# pse84 register map
Vendor: Cypress Semiconductor; Series: PSE84; File version: 1.0
CPU: CM33 r0p1, little endian, MPU, FPU, VTOR, 3 interrupt priority bits
Registers are 32-bit, read-write, reset 0x0 unless marked. A register's access mark holds for its fields unless they carry their own. Offsets are from the block's base; [hi:lo] are bit positions; lines under a group give offsets from that group; {n}, {i} and the like mark numbered series; 'fields as' and 'values as' point back to an identical list; <NAME> marks a mode.

## SAR
Base 0x42E80000
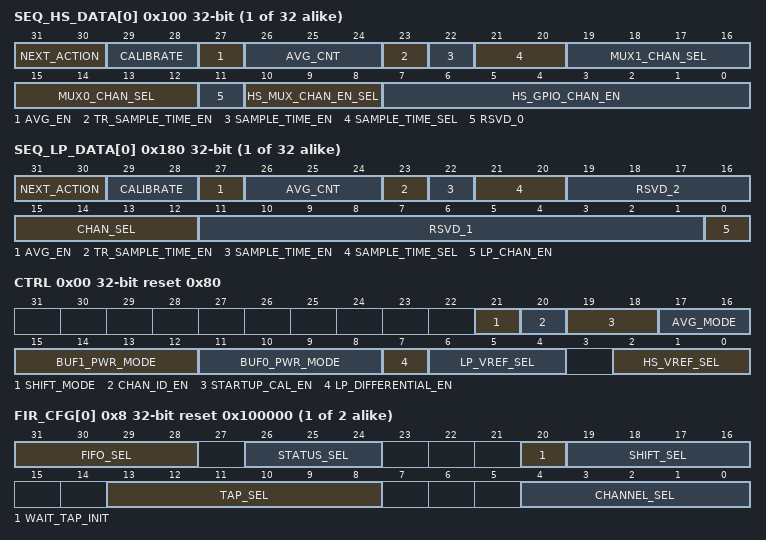
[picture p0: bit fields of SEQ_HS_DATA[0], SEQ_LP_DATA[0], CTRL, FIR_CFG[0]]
{0x100+4i} SEQ_HS_DATA[{i}] (i=0..31) — SAR Sequencer High Speed Data (only accessible if ACTRLR.STATUS.MODE=0)
  [31:30] NEXT_ACTION — Next Addr Field
    0=STOP (assert SAR_DONE and SAR_EOS condition and go to idle. This action is used to indicate the end of a scan.); 1=GO_TO_ENTRY_ADDR (assert SAR_EOS condition and jump to Entry Addr. This action is used for continuous operation. In continuous operation, disabling the SAR (AC.SAR_EN=0) is the only mechanism available to cease SAR operation (without disabling the entire AC).); 2=GO_TO_NEXT (Go to next addr. This action is used to continue to a next state in a given scan.); 3=RSVD (N/A)
  [29:28] CALIBRATE — Real Time Calibration Request. This signals the ADC to initiate a real-time calibration process during an ADC scan.
    0=DISABLED (Calibration Disabled); 1=OFFSET_AND_LINEARITY (Calibrate both Offset and Linearity); 2=OFFSET (Callibrate Offset only); 3=LINEARITY (Callibrate Linearity only)
  [27] AVG_EN — Average Enable This field is ignored if SAR_STA_CFG.CTRL.AVG_MODE=DISABLED. This field applies to all enabled channels (HS_GPIO_CHAN_EN and HS_MUX_CHAN_EN_SEL). 0 = averaging disabled 1 = averaging enabled If SAR_STA_CFG.CTRL.AVG_MODE=ACCUNDUMP, the enabled channels will be sampled, converted, and accumulated back to back (amount set by AVG_CNT). After AVG_CNT times, the accumulated results for each enabled channels are optionally shifted (set by SAR_STA_CFG.GPIO(MUX)_CHAN_CFG.AVG_SHIFT and SAR_STA_CFG.CTRL.SHIFT_MODE). If SAR_STA_CFG.CTRL.AVG_MODE=INTERLEAVED, the enabled channels will be sampled, converted, and accumulated once per scan (amount set by AVG_CNT). After AVG_CNT scans, the accumulated results for each enabled channels are optionally shifted (set by SAR_STA_CFG.GPIO(MUX)_CHAN_CFG.AVG_SHIFT and SAR_STA_CFG.CTRL.SHIFT_MODE). Requirements for using interleaved averaging: 1. The Entry Address state must have AVG_EN set. 2. The same value for AVG_CNT must be used across all states with AVG_EN set. 3. The AC cannot trigger the ADC with different multiple Entry Addresses (scans). 4. The SAR generates a SAR_DONE status at the end of every scan (unless confgured for continuous operation at which point only a SAR_EOS is generated), regardless of the value of AVG_CNT. If all channels in the scan are averaged, the AC can poll the SAR_RESULT or any of the SAR_(FIR)_FIFO_DONE triggers to determine when the averaged results are available. If only a subset of channels are averaged in a scan, it is up to the AC to count the number of scans to determine when the averaged results are available.
  [26:24] AVG_CNT — Averaging Count for channels that have averaging enabled (AVG_EN). A channel will be sampled and accumulated (1<<(AVG_CNT+1)) = [2..256] times. If SAR_STA_CFG.GPIO(MUX)_CHAN_CFG.AVG_SHIFT for an enabled channel is set, the accumulated samples are right shifted based on the value of SAR_STA_CFG.CTRL.SHIFT_MODE: SAR_STA_CFG.CTRL.SHIFT_MODE=TWELVE: After the last accumulation, the result is shifted back to 12 bits SAR_STA_CFG.CTRL.SHIFT_MODE=SIXTEEN: After the last accumulation, if avg_cnt >=32 the result will be shifted back to 16-bits, if avg_cnt < 32, no shift will be done as the result already is guaranteed to fit in 16 bits.
  [23] TR_SAMPLE_TIME_EN — Trigger Sample Time Enable. This field must always remain 0. For risk mitigation purposes only: this bit only applies to the first SAR table entry pointed to by the Autonomous Controller on a trigger if additional sample time is required. When this bit is set, the sample time on this first triggered table entry is SAR_STA_CFG.TR_SAMPLE_TIME.HS_SAMPLE_TIME. This only applies to when the table entry is first triggered. In continuous mode, when this table entry is executed again, the SAMPLE_TIME_EN/SAMPLE_TIME_SEL will be used.
  [22] SAMPLE_TIME_EN — Sample Time Enable. If this bit is set, then the start of conversion for this SAR table entry will be delayed by the sample time pointed to in SAMPLE_TIME_SEL
  [21:20] SAMPLE_TIME_SEL — Sample Time Select. Choose from 1 of 4 available Sample Times in SAR_STA_CFG.SAMPLE_TIME registers
  [19:16] MUX1_CHAN_SEL — MUX1 Channel Sel (See MUX0_CHAN_SEL) (This field is not used if HS_MUX_CHAN_EN_SEL = DISABLED or MUX0_SINGLE_ENDED or MUX0_PSEUDO_DIFF)
  [15:12] MUX0_CHAN_SEL — MUX0 Channel Sel (This field is not used if HS_MUX_CHAN_EN_SEL = DISABLED or MUX1_SINGLE_ENDED)
    {v}=MUX_CHANNEL_{v} (mux configured by settings in SAR_STA_CFG.MUX_CHAN_CFG{v}) (v=0..15)
  [11] RSVD_0
  [10:8] HS_MUX_CHAN_EN_SEL — Enable and Selection for HS Muxed SAR Channels
    0=DISABLED; 1=MUX0_SINGLE_ENDED (One Single Ended Conversion (configured by MUX0_CHAN_SEL)); 2=MUX1_SINGLE_ENDED (One Single Ended Conversion (configured by MUX1_CHAN_SEL)); 3=MUX0_AND_MUX1_SINGLE_ENDED (Two Simultaneously Sampled Single Ended Conversions (configured by MUX0_CHAN_SEL and MUX1_CHAN_SEL)); 4=MUX0_PSEUDO_DIFF (One Pseudo differential conversion (configured by MUX0_CHAN_SEL)); 5=RSVD_0 (N/A); 6=RSVD_1 (N/A); 7=RSVD_2 (N/A)
  [7:0] HS_GPIO_CHAN_EN — Enables for HS GPIO SAR Channels For each bit in this field: 0- HS GPIO SAR Channel is disabled 1- HS GPIO SAR Channel is enabled [0]: Channel 0, configured by SAR_STA_CFG.GPIO_CHAN_CFG0 [1]: Channel 1, configured by SAR_STA_CFG.GPIO_CHAN_CFG1 [2]: Channel 2, configured by SAR_STA_CFG.GPIO_CHAN_CFG2 [3]: Channel 3, configured by SAR_STA_CFG.GPIO_CHAN_CFG3 [4]: Channel 4, configured by SAR_STA_CFG.GPIO_CHAN_CFG4 [5]: Channel 5, configured by SAR_STA_CFG.GPIO_CHAN_CFG5 [6]: Channel 6, configured by SAR_STA_CFG.GPIO_CHAN_CFG6 [7]: Channel 7, configured by SAR_STA_CFG.GPIO_CHAN_CFG7
{0x180+4i} SEQ_LP_DATA[{i}] (i=0..31) — SAR Sequencer Low Power Data (only accessible if ACTRLR.STATUS.MODE=0)
  [31:30] NEXT_ACTION — Next Addr Field
    values as SEQ_HS_DATA[0].NEXT_ACTION
  [29:28] CALIBRATE — Real Time Calibration Request. This signals the ADC to initiate a real-time calibration process during an ADC scan.
    values as SEQ_HS_DATA[0].CALIBRATE
  [27] AVG_EN — Average Enable This field is ignored if SAR_STA_CFG.CTRL.AVG_MODE=DISABLED. This field applies to all enabled channels (HS_GPIO_CHAN_EN and HS_MUX_CHAN_EN_SEL). 0 = averaging disabled 1 = averaging enabled If SAR_STA_CFG.CTRL.AVG_MODE=ACCUNDUMP, the enabled channels will be sampled, converted, and accumulated back to back (amount set by AVG_CNT). After AVG_CNT times, the accumulated results for each enabled channels are optionally shifted (set by SAR_STA_CFG.GPIO(MUX)_CHAN_CFG.AVG_SHIFT and SAR_STA_CFG.CTRL.SHIFT_MODE). If SAR_STA_CFG.CTRL.AVG_MODE=INTERLEAVED, the enabled channels will be sampled, converted, and accumulated once per scan (amount set by AVG_CNT). After AVG_CNT scans, the accumulated results for each enabled channels are optionally shifted (set by SAR_STA_CFG.GPIO(MUX)_CHAN_CFG.AVG_SHIFT and SAR_STA_CFG.CTRL.SHIFT_MODE). Requirements for using interleaved averaging: 1. The Entry Address state must have AVG_EN set. 2. The same value for AVG_CNT must be used across all states with AVG_EN set. 3. The AC cannot trigger the ADC with different multiple Entry Addresses (scans). 4. The SAR generates a SAR_DONE status at the end of every scan (unless confgured for continuous operation at which point only a SAR_EOS is generated), regardless of the value of AVG_CNT. If all channels in the scan are averaged, the AC can poll the SAR_RESULT or any of the SAR_(FIR)_FIFO_DONE triggers to determine when the averaged results are available. If only a subset of channels are averaged in a scan, it is up to the AC to count the number of scans to determine when the averaged results are available.
  [26:24] AVG_CNT — Averaging Count for channels that have averaging enabled (AVG_EN). A channel will be sampled and accumulated (1<<(AVG_CNT+1)) = [2..256] times. If SAR_STA_CFG.GPIO(MUX)_CHAN_CFG.AVG_SHIFT for an enabled channel is set, the accumulated samples are right shifted based on the value of SAR_STA_CFG.CTRL.SHIFT_MODE: SAR_STA_CFG.CTRL.SHIFT_MODE=TWELVE: After the last accumulation, the result is shifted back to 12 bits SAR_STA_CFG.CTRL.SHIFT_MODE=SIXTEEN: After the last accumulation, if avg_cnt >=32 the result will be shifted back to 16-bits, if avg_cnt < 32, no shift will be done as the result already is guaranteed to fit in 16 bits.
  [23] TR_SAMPLE_TIME_EN — Trigger Sample Time Enable. This field must always remain 0. For risk mitigation purposes only: this bit only applies to the first SAR table entry pointed to by the Autonomous Controller on a trigger if additional sample time is required. When this bit is set, the sample time on this first triggered table entry is SAR_STA_CFG.TR_SAMPLE_TIME.LP_SAMPLE_TIME. This only applies to when the table entry is first triggered. In continuous mode, when this table entry is executed again, the SAMPLE_TIME_EN/SAMPLE_TIME_SEL will be used.
  [22] SAMPLE_TIME_EN — Sample Time Enable. If this bit is set, then the start of conversion for this SAR table entry will be delayed by the sample time pointed to in SAMPLE_TIME_SEL
  [21:20] SAMPLE_TIME_SEL — Sample Time Select. Choose from 1 of 4 available Sample Times for the static config
  [19:16] RSVD_2
  [15:12] CHAN_SEL — LP Channel Select
    values as SEQ_HS_DATA[0].MUX0_CHAN_SEL
  [11:1] RSVD_1
  [0] LP_CHAN_EN — LP Channel Enable
0x400 STA group — SAR static configuration registers
  0x00 CTRL reset 0x80 — SAR Control register (only accessible if ACTRLR.STATUS.MODE=0)
    [21] SHIFT_MODE — If GPIO(MUX)_CHAN_CFG.AVG_SHIFT is enabled for a given channel, shift the result to support 12 or 16-bit resolutions. This field does not impact FIR outputs.
      0=TWELVE (TWELVE: After the last accumulation, the result is shifted back to 12 bits); 1=SIXTEEN (SIXTEEN: After the last accumulation, if SEQ_HS(LP)_DATA.AVG_CNT >=32 the result will be shifted back to 16-bits, if SEQ_HS(LP)_DATA.AVG_CNT < 32, no shift will be done as the result already is guaranteed to fit in 16 bits.)
    [20] CHAN_ID_EN — Channel Number Identifier Enable
      0=DISABLED (Data stored in FIFO (selected by GPIO_CHAN_CFG.FIFO_SEL or MUX_CHAN_CFG.FIFO_SEL) does not include Channel Number Identifier. FIFO data is SAR result sign extended to 32-bits.); 1=ENABLED (Data stored in FIFO (selected by GPIO_CHAN_CFG.FIFO_SEL ot MUX_CHAN_CFG.FIFO_SEL) does include Channel Number Identifier. MSB of FIFO data ([31:24]) is defined as follows: [27:24]: GPIO Channel Number (Valid numbers are 0-7) [31:28]: Mux Channel Number (Valid numbers are 0-15) SAR result sign extended to 24-bits. NOTE: FIR data that is written to a FIFO does not have an associated channel ID as the data can be up to 32-bits. FIR data should always be written to dedicated FIFOs.)
    [19:18] STARTUP_CAL_EN — Startup calibration request This field is used to request a calibration process whenever the SAR is powered up (i.e. when AC.SAR.EN toggles from 0 to 1).
      0=DISABLED (Startup calibration Disabled); 1=OFFSET_AND_LINEARITY (calibrate both Offset and Linearity); 2=OFFSET (callibrate Offset only); 3=LINEARITY (callibrate Linearity only)
    [17:16] AVG_MODE — Averaging mode applied to all channels in a scan where averaging is enabled
      0=DISABLED; 1=ACCUNDUMP (Accumulate and Dump (1st order accumulate and dump filter): enabled channels for a given SEQ_HS(LP)_DATA state with AVG_EN set will be accumulated back to back and optionally shifted (if GPIO(MUX)_CHAN_CFG.SHIFT_EN is set). The number of accumulations is set by SEQ_HS(LP)_DATA.AVG_CNT.); 2=INTERLEAVED (DO NOT USE for PSE84 *A0 silicon Interleaved: enabled channels of SEQ_HS(LP)_DATA state with AVG_EN set will be accumulated once per scan and optionally shifted (if GPIO(MUX)_CHAN_CFG.SHIFT_EN is set). The number of accumulations is set by SEQ_HS(LP)_DATA.AVG_CNT.); 3=RSVD (N/A)
    [15:12] BUF1_PWR_MODE — Output buffer power level: see description of BUF0_PWR_MODE
    [11:8] BUF0_PWR_MODE — Buffer zero power level
      0=OFF; 1=ULTRA_LOW (Buffer quiscent current of 15uA, input common mode of 0.2V to VDDA-1V, gain bandwidth 30kHz); 2=ULTRA_LOW_RAIL (Buffer quiscent current of 35uA, input common mode of 0.2V to VDDA-0.2V, gain bandwidth 30kHz); 3=LOW (Do Not Use); 4=LOW_RAIL (Buffer quiscent current of 150uA, input common mode of 0.2V to VDDA-0.2V, gain bandwidth 350kHz); 5=MEDIUM (Do Not Use); 6=MEDIUM_RAIL (Buffer quiscent current of 200uA, input common mode of 0.2V to VDDA-0.2V, gain bandwidth 700kHz); 7=HIGH (Do Not Use); 8=HIGH_RAIL (Buffer quiscent current of 600uA, input common mode of 0.2V to VDDA-0.2V, gain bandwidth 1.75MHz); 9=ULTRA_HIGH (Do Not Use); 10=ULTRA_HIGH_RAIL (Buffer quiscent current of 800uA, input common mode of 0.2V to VDDA-0.2V, gain bandwidth 2.8MHz); {v}=RSVD_{v-11} (N/A) (v=11..15)
    [7] LP_DIFFERENTIAL_EN — Low Power Differential Enable This field is only used for LP mode and is applied to all Mux Channels.
      0=DISABLED (Single ended operation (MUX_CHAN_CFG[X].NEG_PIN_SEL and MUX_CHAN_CFG[X].NEG_COEFF_SEL are ignored)); 1=ENABLED (Differential operation MUX_CHAN_CFG[X].NEG_PIN_SEL and MUX_CHAN_CFG[X].NEG_COEFF_SEL are used.)
    [6:4] LP_VREF_SEL — See HS_VREF_SEL
    [2:0] HS_VREF_SEL — ADC Core VREF selection
      0=VDDA (VREF set to VDDA. The internal reference buffer is off, and an external capacitor is not used.); 1=VREF_EXT (VREF set to external reference (provided through GPIO). The internal reference buffer is off, and an external capacitor is optional.); 2=VBGR (VREF set to internal bandgap reference. The internal reference buffer is on, and an external capacitor is mandatory for HS mode and optional for LP mode.); 3=VDDA_BY_2 (VREF set to internal VDDA divider (VDDA/2). The internal reference buffer is on, and an external capacitor is not mandatory for HS mode and optional for LP mode.); 4=PRB_VREF0 (VREF set to internal PRB Reference 0. The internal reference buffer is on, and an external capacitor is mandatory for both HS and LP modes.); 5=PRB_VREF1 (VREF set to internal PRB Reference 0. The internal reference buffer is on, and an external capacitor is mandatory for both HS and LP modes.); 6=RSVD_0 (N/A); 7=RSVD_1 (N/A)
  0x04 HS_SAMP_CFG reset 0x3FF — SAR HS Sampler Configuration register (only accessible if ACTRLR.STATUS.MODE=0)
    [9:0] HS_SAMP_EN — HS Sampler Enables, all ON by default If an application is only using a subset of samplers, the unused ones can be disabled (using this field) to reduce SAR power consumption.
  {0x8+4j} FIR_CFG[{j}] (j=0..1) reset 0x100000 — FIR Configuration register (only accessible if ACTRLR.STATUS.MODE=0)
    [31:28] FIFO_SEL — FIFO selections. Select 1 of the 8 for FIFO data storage The FIFO must be configured to support the number of desired FIFOs (LPPASS_MMIO.FIFO_STA_CFG.CFG.SEL)
      0=DISABLED (N/A); {v}=FIFO_{v-1} (N/A) (v=1..8); {v}=RSVD_{v-9} (N/A) (v=9..15)
    [26:24] STATUS_SEL — Status selections.
      0=DISABLED (N/A); {v}=STATUS_STRUCT_{v-1} (N/A) (v=1..4); 5=RSVD_0 (N/A); 6=RSVD_1 (N/A); 7=RSVD_2 (N/A)
    [20] WAIT_TAP_INIT — Wait for TAP_SEL number before outputing the first valid data
      0=DISABLED (The FIR will produce a SAR_FIR0(1)_DONE trigger after every update (regardless of the number of filled taps)); 1=ENABLED (The FIR will wait for TAP_SEL+1 locations to be filled prior to producing a SAR_FIR0(1)_DONE trigger.)
    [19:16] SHIFT_SEL — FIR Shift Select Shift the FIR output right by the number in this field
    [13:8] TAP_SEL — FIR Tap Select FIR Tap Select = TAP_SEL+1, range 1..64
    [4:0] CHANNEL_SEL — Channel selection for FIR input The FIR input data is the final output of the selected channel (i.e. if a channel is configured for averaging, the FIR will only receive the final averaged value (no intermediate accumulated values are sent to the FIR)).
      0=DISABLED (N/A); {v}=GPIO_CHANNEL_{v-1} (N/A) (v=1..8); {v}=MUX_CHANNEL_{v-9} (N/A) (v=9..24); {v}=RSVD_{v-25} (N/A) (v=25..31)
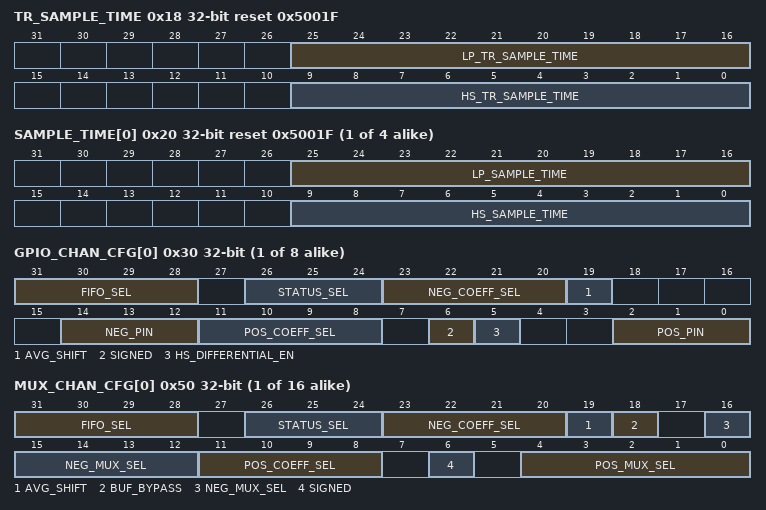
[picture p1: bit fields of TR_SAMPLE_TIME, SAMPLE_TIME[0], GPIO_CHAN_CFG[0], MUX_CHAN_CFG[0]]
  0x18 TR_SAMPLE_TIME reset 0x5001F — SAR Trigger Sample Time (Risk Mitigation Only)
    [25:16] LP_TR_SAMPLE_TIME — Low Power (LP) Trigger Sample Time This field is for risk mitigation purposes only. This field is only applicable if TR_SAMPLE_TIME_EN is set by the Entry Address pointed to by the Autonomous Controller. LP_TR_SAMPLE_TIME sets the number of LP clock cycles to allow for sampling. Entry Address Sample Time = LP_TR_SAMPLE_TIME+1, range 1..1024
    [9:0] HS_TR_SAMPLE_TIME — High Speed (HS) Trigger Sample Time This field is for risk mitigation purposes only. This field is only applicable if TR_SAMPLE_TIME_EN is set by the Entry Address pointed to by the Autonomous Controller. HS_TR_SAMPLE_TIME sets the number of HS clock cycles to allow for sampling of the first address (Entry Address) of a scan. Entry Address Sample Time = HS_TR_SAMPLE_TIME+1, range 1..1024
  {0x20+4j} SAMPLE_TIME[{j}] (j=0..3) reset 0x5001F — Sample control register (only accessible if ACTRLR.STATUS.MODE=0)
    [25:16] LP_SAMPLE_TIME — Sample time (aperture) in LP clock cycles (4MHz). Sample time = SAMPLE_TIME+1, range 1..1024
    [9:0] HS_SAMPLE_TIME — Sample time (aperture) in HS clock cycles (nominally 80MHz). Sample time = SAMPLE_TIME+1, range 1..1024
  {0x30+4j} GPIO_CHAN_CFG[{j}] (j=0..7) — SAR HS Sampler Configuration register
    [31:28] FIFO_SEL — FIFO selections. Select 1 of the 8 for FIFO data storage The FIFO must be configured to support the number of desired FIFOs (LPPASS_MMIO.FIFO_STA_CFG.CFG.SEL)
      values as STA.FIR_CFG[0].FIFO_SEL
    [26:24] STATUS_SEL — Status selections.
      values as STA.FIR_CFG[0].STATUS_SEL
    [23:20] NEG_COEFF_SEL — See POS_COEFF_SEL
    [19] AVG_SHIFT — Average Shift Enable This field is only valid if the following conditions are met: Averaging is configured for accumulate and dump or interleaved: CTRL.AVG_MODE=1,2 Averaging is enabled for particular state in the sequence table: SEQ_HS_DATA.AVG_EN=1 The amount of shifting is set by CTRL.SHIFT_MODE.
    [14:12] NEG_PIN — Negative Input Assignment see POS_PIN
    [11:8] POS_COEFF_SEL — Positive Input Coefficient Select
      0=DISABLED (N/A); {v}=CHAN_COEFF{v-1} (N/A) (v=1..8); {v}=RSVD_{v-9} (N/A) (v=9..15)
    [6] SIGNED — Output data as a signed value
      0=UNSIGNED (Default: result data is unsigned (zero extended if needed)); 1=SIGNED (result data is signed (sign extended if needed))
    [5] HS_DIFFERENTIAL_EN — High Speed Differential Enable
      0=DISABLED (Channel configured for single ended operation (NEG_PIN_SEL and NEG_COEFF_SEL are ignored)); 1=ENABLED (Channel configured for pseudo differential operation (NEG_PIN_SEL and NEG_COEFF_SEL are used))
    [2:0] POS_PIN — Positive Input Assignment
      {v}=P{v} (SAR/PTC GPIO Pin {v}. See product datasheet for specific pin number.) (v=0..7)
  {0x50+4j} MUX_CHAN_CFG[{j}] (j=0..15) — High Speed / Low Power Muxed Channel configuration register (Channel 0 routing is used for default routing (i.e. when the SAR gets enabled) (only accessible if ACTRLR.STATUS.MODE=0)
    [31:28] FIFO_SEL — FIFO selections. Select 1 of the 8 for FIFO data storage The FIFO must be configured to support the number of desired FIFOs (LPPASS_MMIO.FIFO_STA_CFG.CFG.SEL)
      values as STA.FIR_CFG[0].FIFO_SEL
    [26:24] STATUS_SEL — Status selections
      values as STA.FIR_CFG[0].STATUS_SEL
    [23:20] NEG_COEFF_SEL — See POS_COEFF_SEL
    [19] AVG_SHIFT — Average Shift Enable This field is only valid if the following conditions are met: Averaging is configured for accumulate and dump or interleaved: CTRL.AVG_MODE=1,2 Averaging is enabled for particular state in the sequence table: SEQ_HS(LP)_DATA.AVG_EN=1 The amount of shifting is set by CTRL.SHIFT_MODE.
    [18] BUF_BYPASS — Channel Buffer bypass
      0=DISABLED (Buffered bypass disabled); 1=ENABLED (Buffered bypass enabled)
    [16:12] NEG_MUX_SEL — Negative Mux Select See POS_MUX_SEL
    [11:8] POS_COEFF_SEL — Positive Input Coefficient Select
      values as STA.GPIO_CHAN_CFG[0].POS_COEFF_SEL
    [6] SIGNED — Output data as a signed value
      values as STA.GPIO_CHAN_CFG[0].SIGNED
    [4:0] POS_MUX_SEL — Positive Mux Select
      0=COREIO_0 (CTBL0 GPIO Pin 1. See product datasheet for specific pin number.); 1=COREIO_1 (CTBL0 GPIO Pin 4. See product datasheet for specific pin number.); 2=COREIO_2 (CTBL0 GPIO Pin 6. See product datasheet for specific pin number.); 3=COREIO_3 (CTBL0 GPIO Pin 7. See product datasheet for specific pin number.); 4=COREIO_4 (CTBL1 GPIO Pin 1. See product datasheet for specific pin number.); 5=COREIO_5 (CTBL1 GPIO Pin 4. See product datasheet for specific pin number.); 6=COREIO_6 (CTBL1 GPIO Pin 6. See product datasheet for specific pin number.); 7=COREIO_7 (CTBL1 GPIO Pin 7. See product datasheet for specific pin number.); 8=CTBL0_OA0 (CTBL0 Opamp0 Output); 9=CTBL0_OA1 (CTBL0 Opamp1 Output); 10=CTBL1_OA0 (CTBL1 Opamp0 Output); 11=CTBL1_OA1 (CTBL1 Opamp1 Output); 12=VREF0 (DAC0 output); 13=VREF1 (DAC1 output); 14=TEMP_SENSOR (Temperature Sensor); {v}=GPIO_{v-15} (SAR/PTC GPIO Pin {v-15}. See product datasheet for specific pin number.) (v=15..22); 23=AMUXBUS_A (Do Not Use); 24=AMUXBUS_B (Do Not Use); 25=VSSA_KELVIN (SAR Ground); {v}=RESEREVED_{v-26} (N/A) (v=26..31)
  {0x90+4j} STATUS_CFG[{j}] (j=0..3) — Global range detect mode register (only accessible if ACTRLR.STATUS.MODE=0)
    [1:0] RANGE_COND — Range condition select.
      0=BELOW (result < RANGE_LOW); 1=INSIDE (RANGE_LOW <= result < RANGE_HIGH); 2=ABOVE (result > RANGE_HIGH); 3=OUTSIDE (result < RANGE_LOW || result >= RANGE_HIGH)
  {0xA0+4j} STATUS_RANGE_LOW[{j}] (j=0..3) — Global range detect low value register (only accessible if ACTRLR.STATUS.MODE=0)
    [31:0] RANGE_LOW — Low threshold for range detect
  {0xB0+4j} STATUS_RANGE_HIGH[{j}] (j=0..3) — Global range detect high value register (only accessible if ACTRLR.STATUS.MODE=0)
    [31:0] RANGE_HIGH — High threshold for range detect
  {0xC0+4j} GPIO_CHAN_RESULT[{j}] (j=0..7) ro reset not defined — High Speed GPIO Channel result register
    [31:0] RESULT — SAR conversion channel result data of the channel. The data is written here if the corresponding bit in CHAN_RESULT_MASK.GPIO_CHAN_RESULT_MASK is set.
  {0xE0+4j} MUX_CHAN_RESULT[{j}] (j=0..15) ro reset not defined — High Speed / Low Power Muxed Channel result register
    [31:0] RESULT — SAR conversion channel result data of the channel. The data is written here if the corresponding bit in CHAN_RESULT_MASK.MUX_CHAN_RESULT_MASK is set.
  {0x120+4j} FIR_RESULT[{j}] (j=0..1) ro reset not defined
    [31:0] RESULT — FIR output data. The data is written here if the corresponding bit in FIR_RESULT_MASK.FIR_RESULT_MASK is set.
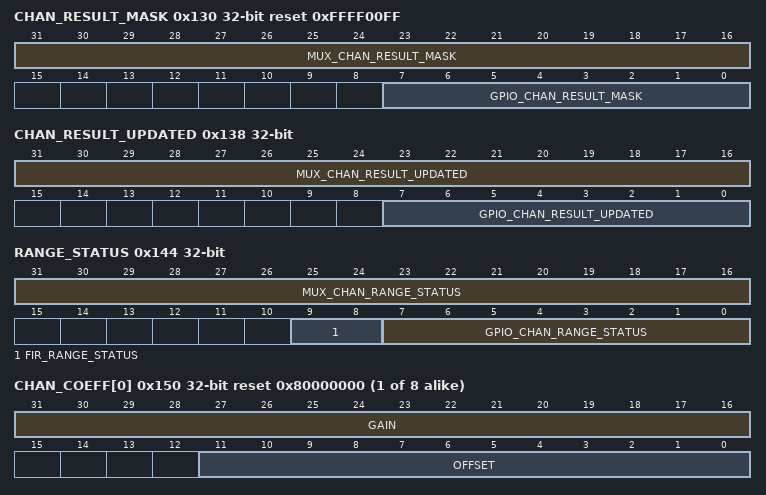
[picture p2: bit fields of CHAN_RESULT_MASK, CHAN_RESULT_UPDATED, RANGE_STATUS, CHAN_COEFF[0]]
  0x130 CHAN_RESULT_MASK reset 0xFFFF00FF — Channel result mask (only accessible if ACTRLR.STATUS.MODE=0)
    [31:16] MUX_CHAN_RESULT_MASK — If set the MUX_CHAN_RESULT.RESULT register will be used to store SAR conversion data and an EOS will be generated at the end of a scan that includes the MUX channel. If this bit isn't set, the channel must be configured to store the result in a FIFO. (Default is for all result registers to be used).
    [7:0] GPIO_CHAN_RESULT_MASK — If set, the GPIO_CHAN_RESULT.RESULT register will be used to store SAR conversion data and an EOS will be generated at the end of a scan that includes the MUX channel. If this bit isn't set, the channel must be configured to store the result in a FIFO. (Default is for all result registers to be used).
  0x134 FIR_RESULT_MASK reset 0x3 — FIR result mask (only accessible if ACTRLR.STATUS.MODE=0)
    [1:0] FIR_RESULT_MASK — If set, the FIR_RESULT.RESULT register will be used to store FIR outputs. If this bit isn't set, the FIR must be configured to store the result in a FIFO. (Default is for the FIR result registers to be used).
  0x138 CHAN_RESULT_UPDATED — Channel result register status
    [31:16] MUX_CHAN_RESULT_UPDATED — If set the corresponding MUX_CHAN_RESULT.RESULT register was updated, i.e. was sampled during the previous scan and, in case of Interleaved averaging, reached the averaging count. If this bit is low then either the channel is not enabled or the averaging count is not yet reached for Interleaved averaging. Write 1 to clear.
    [7:0] GPIO_CHAN_RESULT_UPDATED — If set the corresponding GPIO_CHAN_RESULT.RESULT register was updated, i.e. was sampled during the previous scan and, in case of Interleaved averaging, reached the averaging count. If this bit is low then either the channel is not enabled or the averaging count is not yet reached for Interleaved averaging. Write 1 to clear.
  0x13C FIR_RESULT_UPDATED — FIR result register status
    [1:0] FIR_RESULT_UPDATED — If set the corresponding FIR_RESULT.RESULT register was updated. If this bit is low then either the FIR is not enabled or the FIR output is not yet available. Write 1 to clear.
  0x140 STATUS ro — Current status of internal SAR registers (mostly for debug)
    [31] BUSY — If high then the SAR is busy with a conversion. This bit is always high when CONTINUOUS (i.e. the last state of a scan has SEQ_HS(LP)_DATA.NEXT_ACTION=GO_TO_ENTRY_ADDR). Except for CONINUOUS mode, firmware should wait for this bit to be low before powering down the SAR (AC.SAR_EN=0).
  0x144 RANGE_STATUS
    [31:16] MUX_CHAN_RANGE_STATUS — MUX Channel Range detect status: hardware sets this bit for each channel if the conversion result (after averaging) of that channel met the condition specified by the MUX_CHAN_CFG.STATUS_SEL registers. Write with '1' to clear bit.
    [9:8] FIR_RANGE_STATUS — FIR Range detect status: hardware sets this bit for each FIR if the FIR output met the condition specified by the FIR_CFG.STATUS_SEL registers. Write with '1' to clear bit.
    [7:0] GPIO_CHAN_RANGE_STATUS — GPIO Channel Range detect status: hardware sets this bit for each channel if the conversion result (after averaging) of that channel met the condition specified by the GPIO_CHAN_CFG.STATUS_SEL registers. Write with '1' to clear bit.
  {0x150+4j} CHAN_COEFF[{j}] (j=0..7) reset 0x80000000 — Channel correction coefficients (only accessible if ACTRLR.STATUS.MODE=0)
    [31:16] GAIN — Gain Correction Coefficient (Default value is gain of 1). This field is intended to correct sources of gain error in the SAR channel (from the GPIO to the SAR ADC input). It is expected that both the channel offset correction coefficient and SAR ADC offset have already been calibrated (i.e. HS(LP)_CAL_MEM values are valid). Multiplies the 12-bit SAR conversion by X.XXXXXXXXXXXXXXX Range is: 1/2^15=(0.000030517578125) to 2-(1/2^15)=(1.999969482421875)
    [11:0] OFFSET — Channel Offset Correction Coefficient (Default value is offset of 0). This field is intended to correct sources of offset error in the SAR channel (from the GPIO to the SAR ADC input). It is expected that the SAR ADC offset has already been calibrated (i.e. HS(LP)_CAL_MEM values are valid). Signed offset values range from -2048 (0x800) to +2047 (0x7FF) is added to 12-bit SAR conversion.
{0x600+8i} FIR0[{i}] (i=0..63) group — SAR FIR0 registers (only accessible if ACTRLR.STATUS.MODE=0)
  0x00 COEF — Coefficient Value
    [15:0] COEF — FIR Coefficient Value The coefficient values can range from -1+1/215 to 1-1/215 with a resolution of 1/215. The coefficient uses twos-complement notation and the decimal point is fixed to the right of the most significant bit. Examples: -0.25 = 0xE000 and 0.25 = 0x2000
  0x04 TAP — Tap Value
    [31:0] TAP — Tap value, in typical operation, software only reads the tap. For debug purposes only, sofware can write to the tap.
{0x800+8i} FIR1[{i}] (i=0..63) group — SAR FIR1 registers (only accessible if ACTRLR.STATUS.MODE=0)
  0x00 COEF — Coefficient Value
    fields as FIR0[0].COEF
  0x04 TAP — Tap Value
    fields as FIR0[0].TAP
0xC00 HS_CAL_MEM group — SAR HS Core Calibration Memory (only accessible when the SAR is disabled (AC.SAR_EN=0) and ACTRLR.STATUS.MODE=0)
  0x14 CALCTRL — SAR HS Core Calibration Control Register
    [31:12] R12
    [11:10] STC — Calibration sample time control
      0=use sample time of 512 clk_lppass cycles; 1=use sample time of 1024 clk_lppass cycles; 2=use sample time of 2048 clk_lppass cycles; 3=use sample time of 32 clk_lppass cycles
    [9:8] AVG — Determines averaging repetitions for calibration
      0=use 16 averaging repititions per calibration value; 1=use 32 averaging repititions per calibration value; 2=use 64 averaging repititions per calibration value; 3=use 2 averaging repititions per calibration value
    [7:1] R1
    [0] OFFDEP — Use the old offset-dependent calibration scheme when this bit is set.
  0x1C CONVCTRL — SAR HS Core Conversion Control Register
    [31:6] R6
    [5] RES_RAW — DO NOT change from Default for *A0 PSE84 Silicon. Output the raw result (13-bit, redundant coding) instead of the processed one (12-bit, binary coding).
    [4] MSB_CTRL — When set, the redistribution time for the MSB decision is extended to two sync periods.
    [3:2] R2
    [1:0] INIT_TC — Choose for how many sync-periods the core-side capacitors are initialized to the common mode voltage, via the OCS switch, after conversion start is received.
      0=CONV_INIT_1 (Initialize for 1 sync-period to the core's common mode voltage before redistribution starts); 1=CONV_INIT_2 (Initialize for 2 sync-period to the core's common mode voltage before redistribution starts); 2=CONV_INIT_4 (Initialize for 4 sync-period to the core's common mode voltage before redistribution starts); 3=CONV_INIT_16 (Initialize for 16 sync-period to the core's common mode voltage before redistribution starts)
  0x20 ADFTMUX — SAR HS Core Analog DFT Multiplexer Control Register
    [31:5] R5
    [4:1] SEL — Select the voltage to be output on the Analog DFT port when ADFTMUX.EN=1
      {v}=SEL_VCM_CH{v} (Select common mode voltage of channel {v} when ADFTMUX.EN=1) (v=0..9); 10=SEL_VCM_CORE (Select common mode voltage of core when ADFTMUX.EN=1); 11=SEL_VAREF (Select positive reference voltage when ADFTMUX.EN=1); 12=SEL_VSSA (Select analog ground when ADFTMUX.EN=1); 13=RSVD_0 (N/A); 14=RSVD_1 (N/A); 15=RSVD_2 (N/A)
    [0] EN — Enable the ADT Mux selection according to ADFTMUX.SEL when set. If unset, the ADFT Mux output port will not be driven from the ADC.
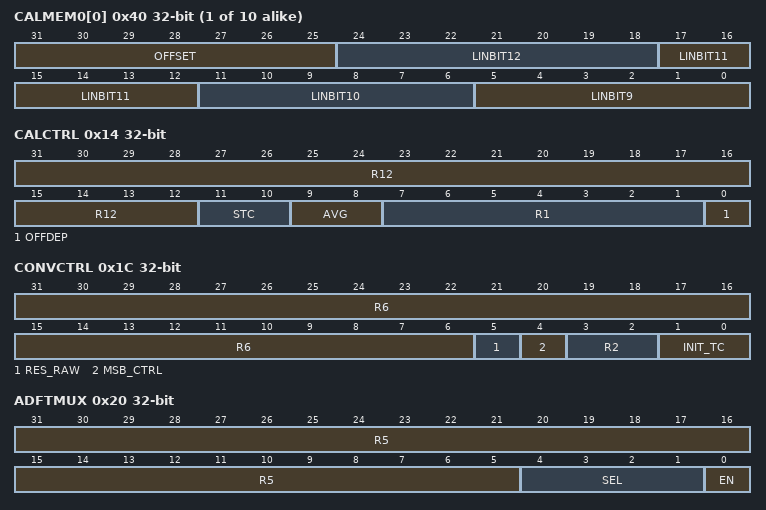
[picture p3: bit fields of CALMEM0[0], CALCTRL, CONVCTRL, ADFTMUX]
  {0x40+4j} CALMEM0[{j}] (j=0..9) — SAR HS Core Channel Calibration Values
    [31:25] OFFSET — Offset calibration value
    [24:18] LINBIT12 — Linearity calibration value for bit 12 (MSB) of the capacitor array
    [17:12] LINBIT11 — Linearity calibration value for bit 11 (MSB-1) of the capacitor array
    [11:6] LINBIT10 — Linearity calibration value for bit 10 (MSB-2) of the capacitor array
    [5:0] LINBIT9 — Linearity calibration value for bit 9 (MSB-3) of the capacitor array
0xC80 LP_CAL_MEM group — SAR LP Core Calibration Memory (only accessible when the SAR is disabled (AC.SAR_EN=0) and ACTRLR.STATUS.MODE=0)
  0x14 CALCTRL — SAR LP Core Calibration Control Register
    fields as HS_CAL_MEM.CALCTRL
  0x1C CONVCTRL — SAR LP Core Conversion Control Register
    [31:6] R6
    [5] RES_RAW — DO NOT change from Default for *A0 PSE84 Silicon. Output the raw result (13-bit, redundant coding) instead of the processed on (12-bit, binary coding)
    [4:0] R0
  0x20 ADFTMUX — SAR LP Core Analog DFT Multiplexer Control Register
    [31:3] R5
    [2:1] SEL — Select the voltage to be output on the Analog DFT port when ADFTMUX.EN=1
      0=SEL_VCM_CORE (Select common mode voltage of core when ADFTMUX.EN=1); 1=SEL_VAREF (Select positive reference voltage when ADFTMUX.EN=1); 2=SEL_VSSA (Select analog ground when ADFTMUX.EN=1); 3=RSVD_0 (N/A)
    [0] EN — Enable the ADT Mux selection according to ADFTMUX.SEL when set. If unset, the ADFT Mux output port will not be driven from the ADC.
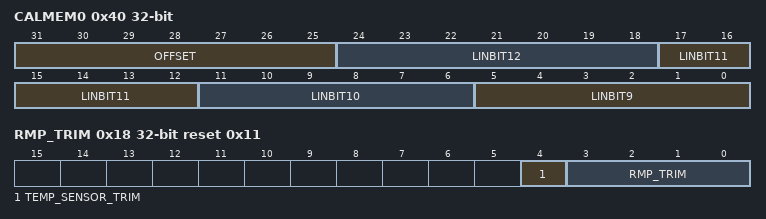
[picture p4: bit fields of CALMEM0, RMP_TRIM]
  0x40 CALMEM0 reset not defined — SAR LP Core Channel Calibration Values
    fields as HS_CAL_MEM.CALMEM0[0]
0xF00 TRIM group — SAR Trim registers (only accessible if ACTRLR.STATUS.MODE=0)
  0x00 BUF0_OFFSET_TRIM — Buffer zero trim control
    [5:0] BUF0_OFFSET_TRIM — buffer 0 offset trim
  0x04 BUF0_SLOPE_OFFSET_TRIM — Buffer zero trim control
    [5:0] BUF0_SLOPE_OFFSET_TRIM — buffer 0 slope offset drift trim
  0x08 BUF0_COMP_TRIM — Buffer zero trim control
    [3:0] BUF0_COMP_TRIM — Buffer 0 Compensation Capacitor Trim Bit<3> is not used Bits<2:0> 000 = 0.1pF 001 = 1.1pF 010 = 2.1pF 011 = 3.1pF 100 = 4.1pF 101 = 5.1pF 110 = 6.1pF 111 = 7.1pF
  0x0C BUF1_OFFSET_TRIM — Buffer one trim control
    [5:0] BUF1_OFFSET_TRIM — buffer 1 offset trim
  0x10 BUF1_SLOPE_OFFSET_TRIM — Buffer one trim control
    [5:0] BUF1_SLOPE_OFFSET_TRIM — buffer 1 slope offset drift trim
  0x14 BUF1_COMP_TRIM — Buffer one trim control
    [3:0] BUF1_COMP_TRIM — see BUF0_COMP_TRIM
  0x18 RMP_TRIM reset 0x11 — Risk Mitigation bits
    [4] TEMP_SENSOR_TRIM — Risk Mitigation Trim bits for SAR Temperature sensor
    [3:0] RMP_TRIM
